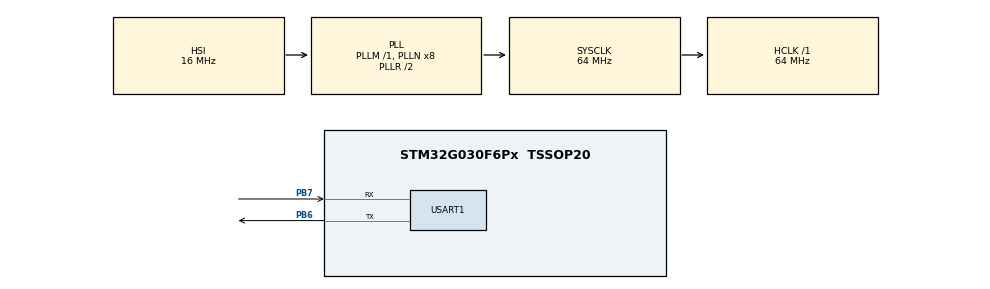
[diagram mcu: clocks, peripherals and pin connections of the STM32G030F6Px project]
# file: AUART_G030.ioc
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Dma.Request0=USART1_RX
Dma.Request1=USART1_TX
Dma.USART1_RX.0.Direction=DMA_PERIPH_TO_MEMORY
Dma.USART1_RX.0.EventEnable=DISABLE
Dma.USART1_RX.0.Instance=DMA1_Channel1
Dma.USART1_RX.0.MemDataAlignment=DMA_MDATAALIGN_BYTE
Dma.USART1_RX.0.MemInc=DMA_MINC_ENABLE
Dma.USART1_RX.0.Mode=DMA_NORMAL
Dma.USART1_RX.0.PeriphDataAlignment=DMA_PDATAALIGN_BYTE
Dma.USART1_RX.0.PeriphInc=DMA_PINC_DISABLE
Dma.USART1_RX.0.Polarity=HAL_DMAMUX_REQ_GEN_RISING
Dma.USART1_RX.0.Priority=DMA_PRIORITY_LOW
Dma.USART1_RX.0.RequestNumber=1
Dma.USART1_RX.0.SignalID=NONE
Dma.USART1_RX.0.SyncEnable=DISABLE
Dma.USART1_RX.0.SyncPolarity=HAL_DMAMUX_SYNC_NO_EVENT
Dma.USART1_RX.0.SyncRequestNumber=1
Dma.USART1_RX.0.SyncSignalID=NONE
Dma.USART1_TX.1.Direction=DMA_MEMORY_TO_PERIPH
Dma.USART1_TX.1.EventEnable=DISABLE
Dma.USART1_TX.1.Instance=DMA1_Channel2
Dma.USART1_TX.1.MemDataAlignment=DMA_MDATAALIGN_BYTE
Dma.USART1_TX.1.MemInc=DMA_MINC_ENABLE
Dma.USART1_TX.1.Mode=DMA_NORMAL
Dma.USART1_TX.1.PeriphDataAlignment=DMA_PDATAALIGN_BYTE
Dma.USART1_TX.1.PeriphInc=DMA_PINC_DISABLE
Dma.USART1_TX.1.Polarity=HAL_DMAMUX_REQ_GEN_RISING
Dma.USART1_TX.1.Priority=DMA_PRIORITY_LOW
Dma.USART1_TX.1.RequestNumber=1
Dma.USART1_TX.1.SignalID=NONE
Dma.USART1_TX.1.SyncEnable=DISABLE
Dma.USART1_TX.1.SyncPolarity=HAL_DMAMUX_SYNC_NO_EVENT
Dma.USART1_TX.1.SyncRequestNumber=1
Dma.USART1_TX.1.SyncSignalID=NONE
Mcu.Family=STM32G0
Mcu.Name=STM32G030F6Px
Mcu.Package=TSSOP20
NVIC.DMA1_Channel1_IRQn=true\:0\:0\:false\:false\:true\:false\:true\:true
NVIC.DMA1_Channel2_3_IRQn=true\:0\:0\:false\:false\:true\:false\:true\:true
NVIC.USART1_IRQn=true\:0\:0\:false\:false\:true\:true\:true\:true
PA13.Mode=Serial_Wire
PA13.Signal=SYS_SWDIO
PA14-BOOT0.Mode=Serial_Wire
PA14-BOOT0.Signal=SYS_SWCLK
PA14-BOOT0__PA15.StandardMode=true
PB0__PB1__PB2__PA8.StandardMode=true
PB3__PB4__PB5__PB6.StandardMode=true
PB6.Mode=Asynchronous
PB6.Signal=USART1_TX
PB7.Mode=Asynchronous
PB7.Signal=USART1_RX
PB7__PB8.StandardMode=true
PC14-OSC32_IN\ (PC14)__PB9.StandardMode=true
ProjectManager.HeapSize=0x200
ProjectManager.StackSize=0x400
ProjectManager.TargetToolchain=EWARM V8.50
RCC.ADCFreq_Value=64000000
RCC.AHBFreq_Value=64000000
RCC.CortexFreq_Value=64000000
RCC.EXTERNAL_CLOCK_VALUE=12288000
RCC.HCLKFreq_Value=64000000
RCC.HSE_VALUE=8000000
RCC.HSI_VALUE=16000000
RCC.LSE_VALUE=32768
RCC.SYSCLKFreq_VALUE=64000000
RCC.SYSCLKSource=RCC_SYSCLKSOURCE_PLLCLK
RCC.VCOOutputFreq_Value=128000000
USART1.VirtualMode-Asynchronous=VM_ASYNC
board=custom

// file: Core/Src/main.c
/* USER CODE BEGIN Header */
/**
  ******************************************************************************
  * @file           : main.c
  * @brief          : Main program body
  ******************************************************************************
  * @attention
  *
  * Copyright (c) 2024 STMicroelectronics.
  * All rights reserved.
  *
  * This software is licensed under terms that can be found in the LICENSE file
  * in the root directory of this software component.
  * If no LICENSE file comes with this software, it is provided AS-IS.
  *
  ******************************************************************************
  */
/* USER CODE END Header */
#include "main.h"
#include "dma.h"
#include "usart.h"
#include "gpio.h"

/* USER CODE BEGIN Includes */
#include <auart.h>
#include <string.h>
/* USER CODE END Includes */

/* USER CODE BEGIN PV */
extern DMA_HandleTypeDef hdma_usart1_rx;
extern DMA_HandleTypeDef hdma_usart1_tx;

static auart_t auart1;
/* USER CODE END PV */

void SystemClock_Config(void);

/* USER CODE BEGIN 0 */
// callback of STM32 HAL
void UART_DMA_RxCpltCallback(UART_HandleTypeDef *huart)
{
  if (huart == &huart1)
    auart_dma_rx_cplt_callback(&auart1);
}

void UART_DMA_RxHalfCpltCallback(UART_HandleTypeDef *huart)
{
  if (huart == &huart1)
    auart_dma_rx_half_cplt_callback(&auart1);
}

void HAL_UART_TxCpltCallback(UART_HandleTypeDef *huart)
{
  if (huart == &huart1)
    auart_tx_cplt_callback(&auart1);
}

void UART_IdleCallback(UART_HandleTypeDef *huart)
{
  if (huart == &huart1)
    auart_idle_callback(&auart1);
}
/* USER CODE END 0 */

int main(void)
{

  /* MCU Configuration--------------------------------------------------------*/

  /* Reset of all peripherals, Initializes the Flash interface and the Systick. */
  HAL_Init();

  /* Configure the system clock */
  SystemClock_Config();

  /* Initialize all configured peripherals */
  MX_GPIO_Init();
  MX_DMA_Init();
  MX_USART1_UART_Init();
  /* USER CODE BEGIN 2 */
  static auart_init_t auart1_init = {
      .dma_tx_start = uart_dma_tx_start,
      .dma_rx_start = uart_dma_rx_start,
      .dma_rx_update_progress = uart_dma_update_progress,
      .dma_tx_abort = uart_dma_abort,
      .dma_rx_abort = uart_dma_abort,
      .get_tick_ms = HAL_GetTick,
      .h_rxdma = &hdma_usart1_rx,
      .h_txdma = &hdma_usart1_tx,
  };

  int res = auart_init(&auart1, &auart1_init);
  /* USER CODE END 2 */

  /* Infinite loop */
  /* USER CODE BEGIN WHILE */
  auart_tx(&auart1, "Hello World!\n", 13);
  auart_tx(&auart1, "Please Input:", 13);

  static uint8_t buffer[128];
  int rx_cnt = 0;
  while (1)
  {
    res = auart_rx(&auart1, buffer + rx_cnt, 128 - rx_cnt);
    if (res > 0)
    {
      // echo back
      auart_tx(&auart1, buffer + rx_cnt, res);

      // check for the end of the string
      for (int i = 0; i < res; i++)
      {
        if (buffer[rx_cnt + i] == '\r')
        {
          auart_tx(&auart1, "\nYou have entered: ", 18);
          auart_tx(&auart1, buffer, rx_cnt + i + 1);
          auart_tx(&auart1, "\r\n", 2);
          rx_cnt = 0;
          res = 0;
          memset(buffer, 0, 128);
          break;
        }
      }

      rx_cnt += res;
    }
    /* USER CODE END WHILE */

  }
}

void SystemClock_Config(void)
{
  RCC_OscInitTypeDef RCC_OscInitStruct = {0};
  RCC_ClkInitTypeDef RCC_ClkInitStruct = {0};

  /** Configure the main internal regulator output voltage
  */
  HAL_PWREx_ControlVoltageScaling(PWR_REGULATOR_VOLTAGE_SCALE1);

  /** Initializes the RCC Oscillators according to the specified parameters
  * in the RCC_OscInitTypeDef structure.
  */
  RCC_OscInitStruct.OscillatorType = RCC_OSCILLATORTYPE_HSI;
  RCC_OscInitStruct.HSIState = RCC_HSI_ON;
  RCC_OscInitStruct.HSIDiv = RCC_HSI_DIV1;
  RCC_OscInitStruct.HSICalibrationValue = RCC_HSICALIBRATION_DEFAULT;
  RCC_OscInitStruct.PLL.PLLState = RCC_PLL_ON;
  RCC_OscInitStruct.PLL.PLLSource = RCC_PLLSOURCE_HSI;
  RCC_OscInitStruct.PLL.PLLM = RCC_PLLM_DIV1;
  RCC_OscInitStruct.PLL.PLLN = 8;
  RCC_OscInitStruct.PLL.PLLP = RCC_PLLP_DIV2;
  RCC_OscInitStruct.PLL.PLLR = RCC_PLLR_DIV2;
  if (HAL_RCC_OscConfig(&RCC_OscInitStruct) != HAL_OK)
  {
    Error_Handler();
  }

  /** Initializes the CPU, AHB and APB buses clocks
  */
  RCC_ClkInitStruct.ClockType = RCC_CLOCKTYPE_HCLK|RCC_CLOCKTYPE_SYSCLK
                              |RCC_CLOCKTYPE_PCLK1;
  RCC_ClkInitStruct.SYSCLKSource = RCC_SYSCLKSOURCE_PLLCLK;
  RCC_ClkInitStruct.AHBCLKDivider = RCC_SYSCLK_DIV1;
  RCC_ClkInitStruct.APB1CLKDivider = RCC_HCLK_DIV1;

  if (HAL_RCC_ClockConfig(&RCC_ClkInitStruct, FLASH_LATENCY_2) != HAL_OK)
  {
    Error_Handler();
  }
}

void Error_Handler(void)
{
  __disable_irq();
  while (1)
  {
  }
}
